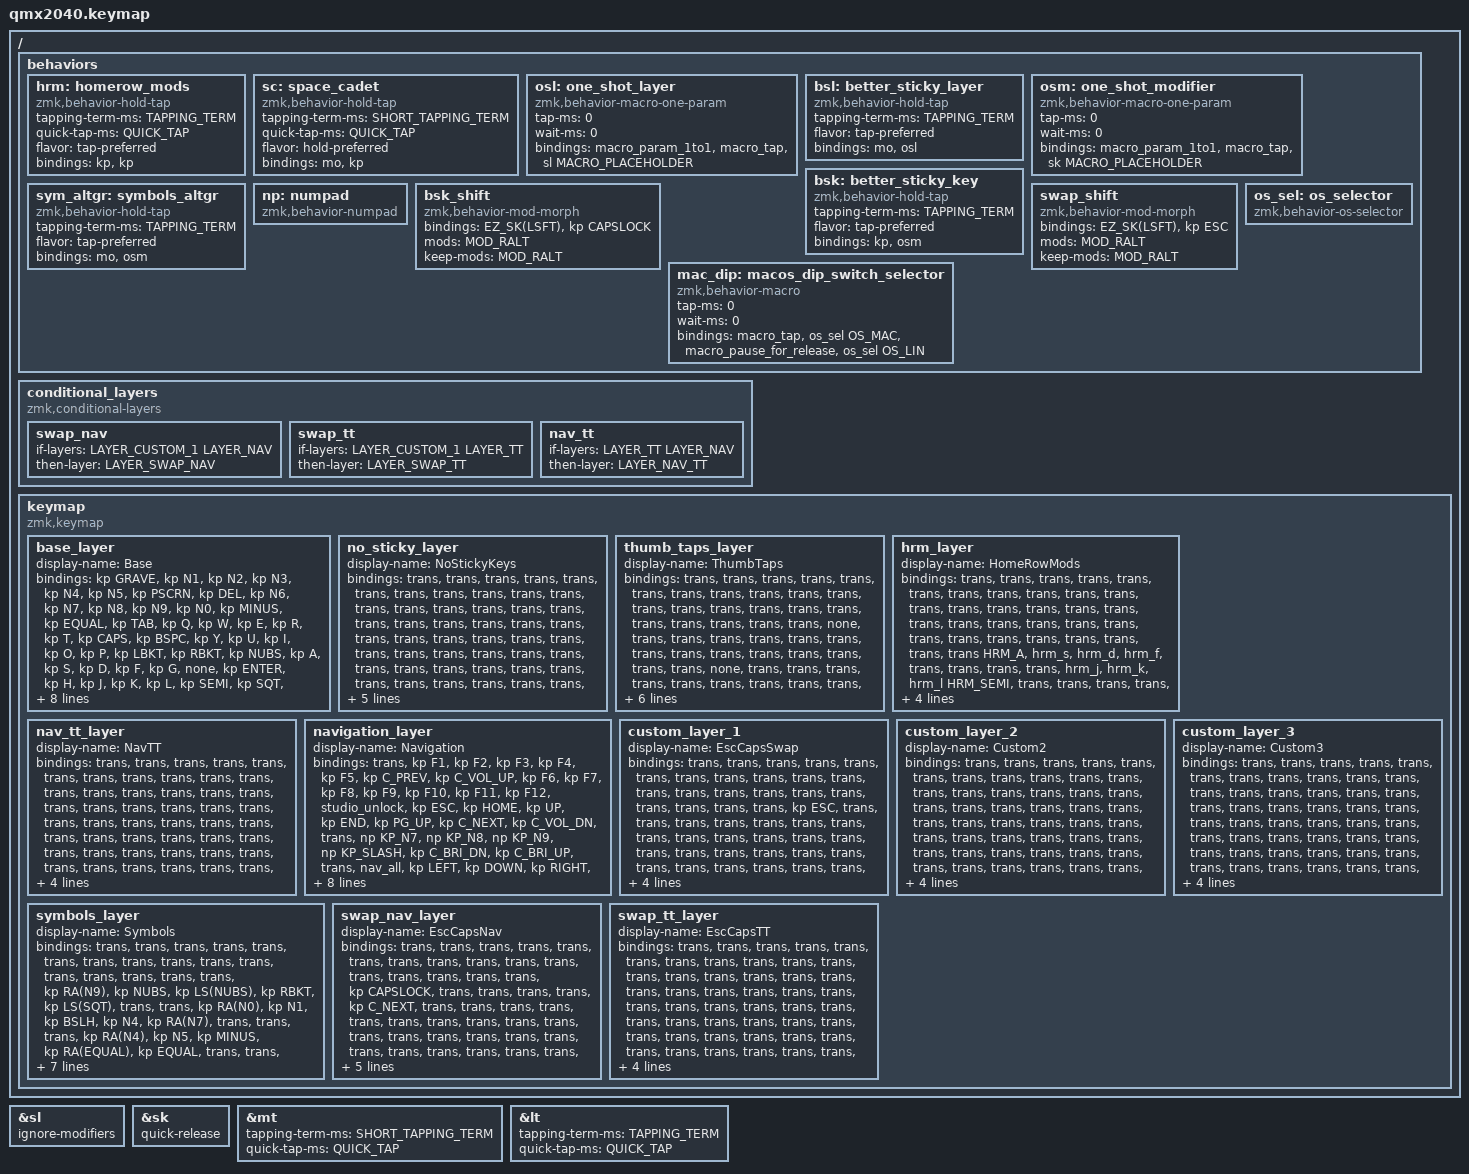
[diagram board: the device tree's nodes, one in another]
// Standard ZMK headers
#include <behaviors.dtsi>
#include <dt-bindings/zmk/keys.h>
#include <dt-bindings/zmk/pointing.h>

// Community module headers
#include <behaviors/mod-hold.dtsi> // Provides helper macros for the mod-hold behavior
#include <dt-bindings/zmk/oskey.h>
#include <behaviors/oskey.dtsi>

// Timing is key
#define TAPPING_TERM       300
#define SHORT_TAPPING_TERM 150
#define QUICK_TAP          200

// Human-readable layer indexes
#define LAYER_BASE          0
#define LAYER_NO_STICKY     1
#define LAYER_TT            2
#define LAYER_HRM           3
#define LAYER_NAV_TT        4
#define LAYER_NAV           5
#define LAYER_CUSTOM_1      6
#define LAYER_CUSTOM_2      7
#define LAYER_CUSTOM_3      8
#define LAYER_SYMBOLS       9
#define LAYER_SWAP_NAV     10
#define LAYER_SWAP_TT      11

// HRM Shorthands
#define HRM_A    &hrm LSHIFT A
#define HRM_S    &hrm LGUI   S
#define HRM_D    &hrm LCTL   D
#define HRM_F    &hrm LALT   F
#define HRM_J    &hrm LALT   J
#define HRM_K    &hrm LCTL   K
#define HRM_L    &hrm LGUI   L
#define HRM_SEMI &hrm LSHIFT SEMI

// HRM Shorthands (mac)
#define MHRM_S &hrm LALT S
#define MHRM_D &hrm LGUI D
#define MHRM_F &hrm LCTL F
#define MHRM_J &hrm LCTL J
#define MHRM_K &hrm LGUI K
#define MHRM_L &hrm LALT L

#define EZ_SL(layer)    bsl   (layer) (layer)
#define EZ_SLMH(layer)  mhbsl (layer) (layer)
#define EZ_SK(mod)      bsk   (mod) (mod)

#define MAC_MORPH(name, base_binding, mac_binding)            \
  name: name {                                                \
    compatible = "zmk,behavior-os-key";                       \
    #binding-cells = <0>;                                     \
    /*               Win            Mac             Lin  */   \
    bindings = <base_binding>, <mac_binding>, <base_binding>; \
  };

&sl { ignore-modifiers; }; // keep one-shot-mods when chained into a one-shot-layer
&sk { quick-release; };    // must-have! (lots of false positives otherwise)

// add our common tap-hold parametesr to the default options
&mt {
  tapping-term-ms = <SHORT_TAPPING_TERM>;
  quick-tap-ms = <QUICK_TAP>;
};

&lt {
  tapping-term-ms = <TAPPING_TERM>;
  quick-tap-ms = <QUICK_TAP>;
};

/ {
  behaviors {
    hrm: homerow_mods {
      compatible = "zmk,behavior-hold-tap";
      #binding-cells = <2>;
      tapping-term-ms = <TAPPING_TERM>;
      quick-tap-ms = <QUICK_TAP>;
      flavor = "tap-preferred";
      bindings = <&kp>, <&kp>;
    };
    sc: space_cadet { // same as lt, but with hold-preferred
      compatible = "zmk,behavior-hold-tap";
      #binding-cells = <2>;
      tapping-term-ms = <SHORT_TAPPING_TERM>;
      quick-tap-ms = <QUICK_TAP>;
      flavor = "hold-preferred";
      bindings = <&mo>, <&kp>;
    };
    // like ZMK's sticky layer (sl) but with a more robust timing
    osl: one_shot_layer {
      compatible = "zmk,behavior-macro-one-param";
      #binding-cells = <1>;
      tap-ms = <0>;
      wait-ms = <0>;
      bindings = <&macro_param_1to1>, <&macro_tap &sl MACRO_PLACEHOLDER>;
    };
    bsl: better_sticky_layer {
      compatible = "zmk,behavior-hold-tap";
      #binding-cells = <2>;
      tapping-term-ms = <TAPPING_TERM>;
      flavor = "tap-preferred";
      bindings = <&mo>, <&osl>;
    };
    // like ZMK's sticky key (sk) but with a more robust timing
    osm: one_shot_modifier {
      compatible = "zmk,behavior-macro-one-param";
      #binding-cells = <1>;
      tap-ms = <0>;
      wait-ms = <0>;
      bindings = <&macro_param_1to1>, <&macro_tap &sk MACRO_PLACEHOLDER>;
    };
    bsk: better_sticky_key {
      compatible = "zmk,behavior-hold-tap";
      #binding-cells = <2>;
      tapping-term-ms = <TAPPING_TERM>;
      flavor = "tap-preferred";
      bindings = <&kp>, <&osm>;
    };

    sym_altgr: symbols_altgr {
      compatible = "zmk,behavior-hold-tap";
      #binding-cells = <2>;
      tapping-term-ms = <TAPPING_TERM>;
      flavor = "tap-preferred";
      // Hold Symbols; tap one-shot AltGr, as on the base layer.
      bindings = <&mo>, <&osm>;
    };

    np: numpad {
      compatible = "zmk,behavior-numpad";
      #binding-cells = <1>;
    };

    bsk_shift: bsk_shift {
      compatible = "zmk,behavior-mod-morph";
      #binding-cells = <0>;
      bindings  = <&EZ_SK(LSFT)>, <&kp CAPSLOCK>;
      mods      = <MOD_RALT>;
      keep-mods = <MOD_RALT>;
    };

    swap_shift: swap_shift {
      compatible = "zmk,behavior-mod-morph";
      #binding-cells = <0>;
      bindings = <&EZ_SK(LSFT)>, <&kp ESC>;
      mods = <MOD_RALT>;
      keep-mods = <MOD_RALT>;
    };

    MOD_HOLD_1(mhmo,  &mo,  0xff)
    MOD_HOLD_2(mhlt,  &lt,  0xff)
    MOD_HOLD_2(mhsc,  &sc,  0xff)
    MOD_HOLD_2(mhbsl, &bsl, 0xff)

    MAC_MORPH(base_gui,  &kp LGUI,       &kp LALT)
    MAC_MORPH(base_alt,  &kp LALT,       &kp LCTL)
    MAC_MORPH(base_ctl,  &EZ_SK(LCTL),   &EZ_SK(LGUI))

    MAC_MORPH(no_sk_ctl, &kp LCTL,       &kp LGUI)

    // Editing shortcuts for the French AZERTY host layout.
    MAC_MORPH(nav_all,     &kp LC(Q), &kp LG(Q)) // AZERTY A
    MAC_MORPH(nav_undo,    &kp LC(W), &kp LG(W)) // AZERTY Z
    MAC_MORPH(nav_cut,     &kp LC(X), &kp LG(X))
    MAC_MORPH(nav_copy,    &kp LC(C), &kp LG(C))
    MAC_MORPH(nav_paste,   &kp LC(V), &kp LG(V))
    MAC_MORPH(nav_redo,    &kp LC(Y), &kp LG(LS(W)))


    MAC_MORPH(swap_tt_alt_l, &mt LALT CAPSLOCK, &mt LCTL CAPSLOCK)

    MAC_MORPH(tt_alt_l,  &mt LALT ESC,   &mt LCTL ESC)
    MAC_MORPH(tt_ctl_l,  &mt LCTL TAB,   &mt LGUI TAB)
    MAC_MORPH(tt_ctl_r,  &mt LCTL ENTER, &mt LGUI ENTER)
    MAC_MORPH(tt_alt_r,  &mt LALT PSCRN, &mt LCTL PSCRN)

    MAC_MORPH(hrm_s,     &hrm LGUI S,    &hrm LALT S)
    MAC_MORPH(hrm_d,     &hrm LCTL D,    &hrm LGUI D)
    MAC_MORPH(hrm_f,     &hrm LALT F,    &hrm LCTL F)
    MAC_MORPH(hrm_j,     &hrm LALT J,    &hrm LCTL J)
    MAC_MORPH(hrm_k,     &hrm LCTL K,    &hrm LGUI K)
    MAC_MORPH(hrm_l,     &hrm LGUI L,    &hrm LALT L)

    os_sel: os_selector {
      compatible = "zmk,behavior-os-selector";
      #binding-cells = <1>;
    };

    mac_dip: macos_dip_switch_selector {
      compatible = "zmk,behavior-macro";
      #binding-cells = <0>;
      tap-ms = <0>;
      wait-ms = <0>;
      bindings = <
        &macro_tap
        &os_sel OS_MAC
        &macro_pause_for_release
        &os_sel OS_LIN
      >;
    };
  };

  conditional_layers {
    compatible = "zmk,conditional-layers";
    swap_nav {
      if-layers = <LAYER_CUSTOM_1 LAYER_NAV>;
      then-layer = <LAYER_SWAP_NAV>;
    };
    swap_tt {
      if-layers = <LAYER_CUSTOM_1 LAYER_TT>;
      then-layer = <LAYER_SWAP_TT>;
    };
    nav_tt {
      if-layers = <LAYER_TT LAYER_NAV>;
      then-layer = <LAYER_NAV_TT>;
    };
  };

  keymap {
    compatible = "zmk,keymap";

    base_layer: base_layer {
      display-name = "Base";
      bindings = <
        &kp GRAVE &kp N1 &kp N2 &kp N3 &kp N4 &kp N5 &kp PSCRN   &kp DEL   &kp N6 &kp N7 &kp N8    &kp N9  &kp N0   &kp MINUS &kp EQUAL
        &kp TAB   &kp Q  &kp W  &kp E  &kp R  &kp T  &kp CAPS    &kp BSPC  &kp Y  &kp U  &kp I     &kp O   &kp P    &kp LBKT  &kp RBKT
        &kp NUBS  &kp A  &kp S  &kp D  &kp F  &kp G  &none       &kp ENTER &kp H  &kp J  &kp K     &kp L   &kp SEMI &kp SQT   &kp BSLH
                  &kp Z  &kp X  &kp C  &kp V  &kp B                        &kp N  &kp M  &kp COMMA &kp DOT &kp FSLH
              &base_gui &base_alt &bsk_shift &mhlt LAYER_NAV SPC &base_ctl   &EZ_SLMH(LAYER_NAV) &mhlt LAYER_NAV SPC &EZ_SK(RALT) &base_alt &base_gui
           &mo LAYER_TT  &mo LAYER_HRM  &mo LAYER_NO_STICKY  &mac_dip  &mo LAYER_CUSTOM_1
      >;
    };

    no_sticky_layer: no_sticky_layer {
      display-name = "NoStickyKeys";
      bindings = <
        &trans &trans &trans &trans &trans &trans &trans &trans &trans &trans &trans &trans &trans &trans &trans
        &trans &trans &trans &trans &trans &trans &trans &trans &trans &trans &trans &trans &trans &trans &trans
        &trans &trans &trans &trans &trans &trans &trans &trans &trans &trans &trans &trans &trans &trans &trans
               &trans &trans &trans &trans &trans               &trans &trans &trans &trans &trans
               &trans &trans &kp LSFT &trans &no_sk_ctl    &mhmo LAYER_NAV &trans &kp RALT &trans &trans
          &trans  &trans  &trans  &trans  &trans
      >;
    };

    thumb_taps_layer: thumb_taps_layer {
      display-name = "ThumbTaps";
      bindings = <
        &trans &trans &trans &trans &trans &trans &trans &trans &trans &trans &trans &trans &trans &trans &trans
        &trans &trans &trans &trans &trans &trans &trans &none &trans &trans &trans &trans &trans &trans &trans
        &trans &trans &trans &trans &trans &trans &trans &none &trans &trans &trans &trans &trans &trans &trans
               &trans &trans &trans &trans &trans                         &trans &trans &trans &trans &trans
           &trans &tt_alt_l &trans &kp BSPC &tt_ctl_l      &tt_ctl_r &mhlt LAYER_NAV SPC &sym_altgr LAYER_SYMBOLS RALT &tt_alt_r &trans
          &trans  &trans  &trans  &trans  &trans
      >;
    };

    hrm_layer: hrm_layer {
      display-name = "HomeRowMods";
      bindings = <
        &trans &trans &trans &trans &trans &trans &trans &trans &trans &trans &trans &trans &trans    &trans &trans
        &trans &trans &trans &trans &trans &trans &trans &trans &trans &trans &trans &trans &trans    &trans &trans
        &trans HRM_A  &hrm_s &hrm_d &hrm_f &trans &trans &trans &trans &hrm_j &hrm_k &hrm_l HRM_SEMI  &trans &trans
               &trans &trans &trans &trans &trans               &trans &trans &trans &trans &trans
               &trans &trans &trans &trans &trans               &trans &trans &trans &trans &trans
          &trans  &trans  &trans  &trans  &trans
      >;
    };

    nav_tt_layer: nav_tt_layer {
      display-name = "NavTT";
      bindings = <
        &trans &trans &trans &trans &trans &trans &trans &trans &trans &trans &trans &trans &trans &trans &trans
        &trans &trans &trans &trans &trans &trans &trans &trans &trans &trans &trans &trans &trans &trans &trans
        &trans &trans &trans &trans &trans &trans &trans &trans &trans &trans &trans &trans &trans &trans &trans
               &trans &trans &trans &trans &trans               &trans &trans &trans &trans &trans
               &trans &trans &trans &kp DEL &kp LS(TAB)         &trans &trans &trans &trans &trans
          &trans  &trans  &trans  &trans  &trans
      >;
    };

    navigation_layer: navigation_layer {
      display-name = "Navigation";
      bindings = <
        &trans         &kp F1  &kp F2   &kp F3   &kp F4    &kp F5    &kp C_PREV &kp C_VOL_UP &kp F6       &kp F7    &kp F8    &kp F9    &kp F10      &kp F11      &kp F12
        &studio_unlock &kp ESC &kp HOME &kp UP   &kp END   &kp PG_UP &kp C_NEXT &kp C_VOL_DN &trans       &np KP_N7 &np KP_N8 &np KP_N9 &np KP_SLASH &kp C_BRI_DN &kp C_BRI_UP
        &trans         &nav_all &kp LEFT &kp DOWN &kp RIGHT &kp PG_DN &kp C_PP   &kp C_MUTE   &np KP_MINUS &np KP_N4 &np KP_N5 &np KP_N6 &np KP_N0    &trans       &trans
                       &nav_undo &nav_cut &nav_copy &nav_paste &nav_redo                    &kp M        &np KP_N1 &np KP_N2 &np KP_N3 &np KP_DOT
                       &trans  &trans   &trans   &trans    &trans                            &trans       &trans &trans &trans &trans
          &trans  &trans  &trans  &trans  &trans
      >;
    };

    custom_layer_1: custom_layer_1 {
      display-name = "EscCapsSwap";
      bindings = <
        &trans &trans &trans &trans &trans &trans &trans &trans &trans &trans &trans &trans &trans &trans &trans
        &trans &trans &trans &trans &trans &trans &kp ESC &trans &trans &trans &trans &trans &trans &trans &trans
        &trans &trans &trans &trans &trans &trans &trans &trans &trans &trans &trans &trans &trans &trans &trans
               &trans &trans &trans &trans &trans               &trans &trans &trans &trans &trans
               &trans &trans &swap_shift &trans &trans &trans &trans &trans &trans &trans
          &trans  &trans  &trans  &trans  &trans
      >;
    };

    custom_layer_2: custom_layer_2 {
      display-name = "Custom2";
      bindings = <
        &trans &trans &trans &trans &trans &trans &trans &trans &trans &trans &trans &trans &trans &trans &trans
        &trans &trans &trans &trans &trans &trans &trans &trans &trans &trans &trans &trans &trans &trans &trans
        &trans &trans &trans &trans &trans &trans &trans &trans &trans &trans &trans &trans &trans &trans &trans
               &trans &trans &trans &trans &trans               &trans &trans &trans &trans &trans
               &trans &trans &trans &trans &trans               &trans &trans &trans &trans &trans
          &trans  &trans  &trans  &trans  &trans
      >;
    };

    custom_layer_3: custom_layer_3 {
      display-name = "Custom3";
      bindings = <
        &trans &trans &trans &trans &trans &trans &trans &trans &trans &trans &trans &trans &trans &trans &trans
        &trans &trans &trans &trans &trans &trans &trans &trans &trans &trans &trans &trans &trans &trans &trans
        &trans &trans &trans &trans &trans &trans &trans &trans &trans &trans &trans &trans &trans &trans &trans
               &trans &trans &trans &trans &trans               &trans &trans &trans &trans &trans
               &trans &trans &trans &trans &trans               &trans &trans &trans &trans &trans
          &trans  &trans  &trans  &trans  &trans
      >;
    };


    // Arsenik Symbols, for a French AZERTY host (Linux/Windows).
    // Positions follow the physical QWERTY grid, independently of letter labels.
    symbols_layer: symbols_layer {
      display-name = "Symbols";
      bindings = <
        &trans &trans &trans &trans &trans &trans &trans &trans &trans &trans &trans &trans &trans &trans &trans
        &trans &kp RA(N9) &kp NUBS &kp LS(NUBS) &kp RBKT &kp LS(SQT) &trans &trans &kp RA(N0) &kp N1 &kp BSLH &kp N4 &kp RA(N7) &trans &trans
        &trans &kp RA(N4) &kp N5 &kp MINUS &kp RA(EQUAL) &kp EQUAL &trans &trans &kp RA(N8) &kp LS(EQUAL) &kp N6 &kp LS(DOT) &kp N3 &trans &trans
               &kp RA(N2) &kp RA(N5) &kp RA(MINUS) &kp N8 &kp RA(N3) &kp RA(N6) &kp FSLH &kp COMMA &kp DOT &kp LS(M)
               &trans &trans &trans &trans &trans &trans &trans &trans &trans &trans
          &trans &trans &trans &trans &trans
      >;
    };


    swap_nav_layer: swap_nav_layer {
      display-name = "EscCapsNav";
      bindings = <
        &trans &trans &trans &trans &trans &trans &trans &trans &trans &trans &trans &trans &trans &trans &trans
        &trans &kp CAPSLOCK &trans &trans &trans &trans &kp C_NEXT &trans &trans &trans &trans &trans &trans &trans &trans
        &trans &trans &trans &trans &trans &trans &trans &trans &trans &trans &trans &trans &trans &trans &trans
        &trans &trans &trans &trans &trans &trans &trans &trans &trans &trans
        &trans &trans &trans &trans &trans &trans &trans &trans &trans &trans
        &trans &trans &trans &trans &trans
      >;
    };

    swap_tt_layer: swap_tt_layer {
      display-name = "EscCapsTT";
      bindings = <
        &trans &trans &trans &trans &trans &trans &trans &trans &trans &trans &trans &trans &trans &trans &trans
        &trans &trans &trans &trans &trans &trans &trans &trans &trans &trans &trans &trans &trans &trans &trans
        &trans &trans &trans &trans &trans &trans &trans &trans &trans &trans &trans &trans &trans &trans &trans
        &trans &trans &trans &trans &trans &trans &trans &trans &trans &trans
        &trans &swap_tt_alt_l &trans &trans &trans &trans &trans &trans &trans &trans
        &trans &trans &trans &trans &trans
      >;
    };
  };
};
